# SF32LB57x register map
File version: 1.0
CPU: CM33 r0p1, little endian, MPU, FPU, 3 interrupt priority bits
Registers are 32-bit, read-write, reset 0x0 unless marked. A register's access mark holds for its fields unless they carry their own. Offsets are from the block's base; [hi:lo] are bit positions; {n}, {i} and the like mark numbered series.

## SPI1
Base 0x50095000
Same registers: SPI2 0x50096000
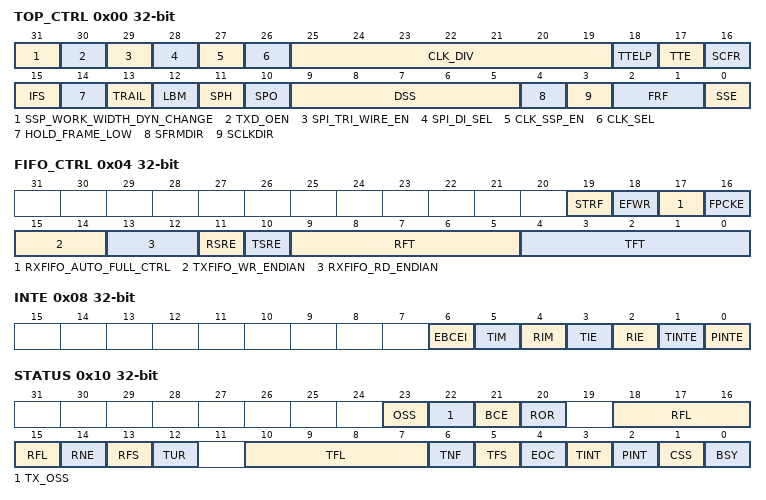
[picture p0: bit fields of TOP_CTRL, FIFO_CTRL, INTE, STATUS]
0x00 TOP_CTRL — Top Control Register
  [31] SSP_WORK_WIDTH_DYN_CHANGE — SSP_WORK_WIDTH_DYN_CHNAGE 1=SP can dynamicly change SSP_TOP_CTRL[9:5] without disabling SSP_TOP_CTRL[0] and re-enabling SSP_TOP_CTRL[0]
  [30] TXD_OEN — TXD_OEN 1=TXD is input 0=TXD is output
  [29] SPI_TRI_WIRE_EN — SPI_THREE_WIRE_MODE_EN 1=enable
  [28] SPI_DI_SEL — Select spi_di source. 0: from port DI. 1: from port DIO.
  [27] CLK_SSP_EN — write 0 to diable clk before clk setting is done
  [26] CLK_SEL — 0: select clk_div as clk_ssp 1: select clk_sys as clk_ssp
  [25:19] CLK_DIV — div ratio from clk_sys
  [18] TTELP — TXD Three-state Enable On Last Phase 0 = TXDx is three-stated 1/2 clock cycle after the beginning of the LSB 1 = TXDx output signal is three-stated on the clock edge that ends the LSB
  [17] TTE — TXD Three-State Enable 0 = TXDx output signal is not three-stated 1 = TXD is three-stated when not transmitting data
  [16] SCFR — Slave Clock Free Running 0 = Clock input to SSPSCLKx is continuously running 1 = Clock input to SSPSCLKx is only active during data transfers.
  [15] IFS — Invert Frame Signal 0 = SSPSFRMx polarity is determined by the PSP polarity bits 1 = SSPSFRMx will be inverted from normal-SSPSFRMx (as defined by the PSP polarity bits). (Works in all frame formats: SPI, SSP, and PSP)
  [14] HOLD_FRAME_LOW — Hold Frame Low Control 1=After this field is set to 1 and the SSP is operating in master mode, the output frame clock ssp_sfrm_gpio will hold low. Used for SPI and NMW Format Rx FIFO Auto Full Control, which makes the frame clock is still low during there's no bit clock, or the data transfers before the stop clock will be discarded.
  [13] TRAIL — Trailing Byte 0 = Trailing bytes are handled by the ltvar Product Number> 1 = Trailing bytes are handled by DMA bursts
  [12] LBM — Loopback Mode (Test Mode Bit) 0 = Normal serial port operation is enabled 1 = Output of TX serial shifter is internally connected to input of RX serial shifter
  [11] SPH — Motorola SPI SSPSCLK phase setting 0 = SSPSCLKx is inactive until one cycle after the start of a frame and active until 1/2 cycle before the end of a frame 1 = SSPSCLKx is inactive until 1/2 cycle after the start of a frame and active until one cycle before the end of a frame
  [10] SPO — Motorola SPI SSPSCLK Polarity Setting 0 = The inactive or idle state of SSPSCLKx is low 1 = The inactive or idle state of SSPSCLKx is high
  [9:5] DSS — SSP Work data size, register bits value 0~31 indicated data size 1~32 bits, usually use data size 8bits, 16bits, 24bits, 32bits
  [4] SFRMDIR — SSP Frame (SSPSFRMx) Direction 0 = Master mode, SSPx port drives SSPSFRMx 1 = Slave mode, SSPx port receives SSPSFRMx
  [3] SCLKDIR — SSP Serial Bit Rate Clock (SSPSCLKx) Direction 0 = Master mode, SSPx port drives SSPSCLKx 1 = Slave mode, SSPx port receives SSPSCLKx
  [2:1] FRF — Frame Format 0x0 = Motorola* Serial Peripheral Interface (SPI) 0x1 = Texas Instruments* Synchronous Serial Protocol (SSP) 0x2 = National Semiconductor Microwire* 0x3 = Frame mode
  [0] SSE — Synchronous Serial Port Enable 0 = SSPx port is disabled 1 = SSPx port is enabled
0x04 FIFO_CTRL — FIFO Control Register
  [19] STRF — Select FIFO For Efwr (Test Mode Bit) Only when the ltEnable FIFO Write/read> field = 1 0 = TXFIFO is selected for both writes and reads through the SSP Data Register 1 = RXFIFO is selected for both writes and reads through the SSP Data Register
  [18] EFWR — Enable FIFO Write/read (Test Mode Bit) 0 = FIFO write/read special function is disabled (normal SSPx operational mode) 1 = FIFO write/read special function is enabled
  [17] RXFIFO_AUTO_FULL_CTRL — Rx FIFO Auto Full Control =1After this field is set to 1 and the SSP is operating in master mode, the SSP FSM returns to IDLE state and stops the ssp_sclk_gpio. When Rx FIFO is full, the SSP FSM continues transferring data after the Rx FIFO is not full. This field is used to avoid an Rx FIFO overrun issue. 1= Enable Rx FIFO auto full control
  [16] FPCKE — FIFO Packing Enable 0 = FIFO packing mode disabled 1 = FIFO packing mode enabled
  [15:14] TXFIFO_WR_ENDIAN — apb_pwdata Write to Tx FIFO Endian 0x0 = txfifo_wdata[31:0] = apb_pwdata[31:0] 0x1 = fifo_wdata[31:0] = {apb_pwdata[15:0], apb_pwdata[31:16]} 0x2 = txfifo_wdata[31:0] = {apb_pwdata[7:0], apb_pwdata[15:8], apb_pwdata[23:16], apb_pwdata[31:24]} 0x3 = txfifo_wdata[31:0] = {apb_pwdata[23:16], apb_pwdata[31:24], apb_pwdata[7:0], apb_pwdata[15:8]}
  [13:12] RXFIFO_RD_ENDIAN — apb_prdata Read from Rx FIFO Endian 0x0 = apb_prdata[31:0] = rxfifo_wdata[31:0] 0x1 = apb_prdata[31:0] = {rxfifo_wdata[15:0], rxfifo_wdata[31:16]} 0x2 = apb_prdata[31:0]= {rxfifo_wdata[7:0], rxfifo_wdata[15:8], rxfifo_wdata[23:16], rxfifo_wdata[31:24]} 0x3 = apb_prdata[31:0]= {rxfifo_wdata[23:16], rxfifo_wdata[31:24], rxfifo_wdata[7:0], rxfifo_wdata[15:8]}
  [11] RSRE — Receive Service Request Enable 0 = DMA service request is disabled 1 = DMA service request is enabled
  [10] TSRE — Transmit Service Request Enable 0 = DMA service request is disabled 1 = DMA service request is enabled
  [9:5] RFT — RXFIFO Trigger Threshold This field sets the threshold level at which RXFIFO asserts interrupt. The level should be set to the preferred threshold value minus 1.
  [4:0] TFT — TXFIFO Trigger Threshold This field sets the threshold level at which TXFIFO asserts interrupt. The level should be set to the preferred threshold value minus 1.
0x08 INTE — Interrupt Enable Register
  [6] EBCEI — Enable Bit Count Error Interrupt 0 = Interrupt due to a bit count error is disabled 1 = Interrupt due to a bit count error is enabled
  [5] TIM — Transmit FIFO Underrun Interrupt Mask 0 = TUR events generate an SSP interrupt 1 = TUR events do NOT generate an SSP interrupt
  [4] RIM — Receive FIFO Overrun Interrupt Mask 0 = ROR events generate an SSP interrupt 1 = ROR events do NOT generate an SSP interrupt
  [3] TIE — Transmit FIFO Interrupt Enable 0 = TXFIFO threshold-level-reached interrupt is disabled 1 = TXFIFO threshold-level-reached interrupt is enabled
  [2] RIE — Receive FIFO Interrupt Enable 0 = RXFIFO threshold-level-reached interrupt is disabled 1 = RXFIFO threshold-level-reached interrupt is enabled
  [1] TINTE — Receiver Time-out Interrupt Enable 0 = Receiver time-out interrupt is disabled 1 = Receiver time-out interrupt is enabled
  [0] PINTE — Peripheral Trailing Byte Interrupt Enable 0 = Peripheral trailing byte interrupt is disabled 1 = Peripheral trailing byte interrupt is enabled
0x0C TO — SPI Time Out Register
  [23:0] TIMEOUT — Timeout Value TIMEOUT value is the value (0 to 2ltsuper 24>-1) that defines the time-out interval. The time-out interval is given by the equation shown in the TIMEOUT Interval Equation.
0x10 STATUS
  [23] OSS — Odd Sample Status 0 = RxFIFO entry has two samples 1 = RxFIFO entry has one sample Note that this bit needs to be looked at only when FIFO Packing is enabled (ltFIFO Packing Enable> field in SSP FIFO Control Register is set). Otherwise, this bit is zero. When SSPx port is in Packed mode and the CPU is used instead of DMA to read the RxFIFO, the CPU should make sure that ltReceive FIFO Not Empty> = 1 AND this field = 0 before it attempts to read the RxFIFO.
  [22] TX_OSS — TX FIFO Odd Sample Status When SSPx port is in packed mode, the number of samples in the TX FIFO is: (ltTransmit FIFO Level>*2 + this field), when ltTransmit FIFO Not Full> = 1 32, when ltTransmit FIFO Not Full> = 0. The TX FIFO cannot accept new data when ltTransmit FIFO Not Full> = 1 and ltTransmit FIFO Level> = 15 and this field = 1. (The TX FIFO has 31 samples). 0 = TxFIFO entry has an even number of samples 1 = TxFIFO entry has an odd number of samples Note that this bit needs to be read only when FIFO Packing is enabled (ltFIFO Packing Enable> in the SSP FIFO Control Register is set). Otherwise, this bit is zero.
  [21] BCE — Bit Count Error 0 = The SSPx port has not experienced a bit count error 1 = The SSPSFRMx signal was asserted when the bit counter was not zero
  [20] ROR — Receive FIFO Overrun 0 = RXFIFO has not experienced an overrun 1 = Attempted data write to full RXFIFO, causes an interrupt request
  [18:15] RFL — Receive FIFO Level This field is the number of entries minus one in RXFIFO. When the value 0x1F is read, the RXFIFO is either empty or full, and software should read the ltReceive FIFO Not Empty> field.
  [14] RNE — Receive FIFO Not Empty 0 = RXFIFO is empty 1 = RXFIFO is not empty
  [13] RFS — Receive FIFO Service Request 0 = RXFIFO level is at or below RFT threshold (RFT) or SSPx port is disabled 1 = RXFIFO level exceeds RFT threshold (RFT), causes an interrupt request
  [12] TUR — Transmit FIFO Underrun 0 = The TXFIFO has not experienced an underrun 1 = A read from the TXFIFO was attempted when the TXFIFO was empty, causes an interrupt if it is enabled (ltTransmit FIFO Underrun Interrupt Mask> in the SSP INT EN Register is 0)
  [10:7] TFL — Transmit FIFO Level This field is the number of entries in TXFIFO.When the value 0x0 is read, the TXFIFO is either empty or full, and software should read the ltTransmit FIFO Not Full> field.
  [6] TNF — Transmit FIFO Not Full 0 = TXFIFO is full 1 = TXFIFO is not full
  [5] TFS — Transmit FIFO Service Request 0 = TX FIFO level exceeds the TFT threshold (TFT + 1) or SSPx port disabled 1 = TXFIFO level is at or below TFT threshold (TFT + 1), causes an interrupt request
  [4] EOC — End Of Chain 0 = DMA has not signaled an end of chain condition 1 = DMA has signaled an end of chain condition
  [3] TINT — Receiver Time-out Interrupt 0 = No receiver time-out is pending 1 = Receiver time-out pending, causes an interrupt request
  [2] PINT — Peripheral Trailing Byte Interrupt 0 = No peripheral trailing byte interrupt is pending 1 = Peripheral trailing byte interrupt is pending
  [1] CSS — Clock Synchronization Status 0 = The SSPx port is ready for slave clock operations 1 = The SSPx port is currently busy synchronizing slave mode signals
  [0] BSY — SSP Busy 0 = SSPx port is idle or disabled 1 = SSPx port is currently transmitting or receiving framed data
0x14 DATA — SPI DATA Register
  [31:0] DATA — DATA This field is used for data to be written to the TXFIFO read from the RXFIFO.
0x18 FRM_HDR_DATA — Frame Header Register
  [31:0] HDR_DATA — frame header data, including cmd addr ect
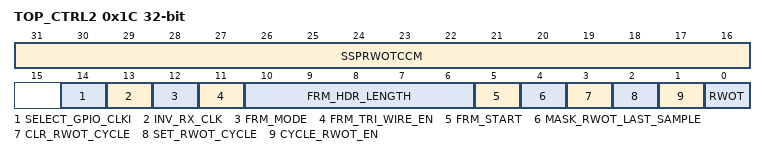
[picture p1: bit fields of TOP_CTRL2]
0x1C TOP_CTRL2 — Top CTRL Register2
  [31:16] SSPRWOTCCM — It's just total ssp_sclk_gpio Cycles The value of this register defines the total number of ssp_sclk_gpio cycles when SSP works in master and RWOT mode. When the rwot_counter matches this value, SSP returns to IDLE state and does not output ssp_sclk_gpio anymore.
  [14] SELECT_GPIO_CLKI — use clki from as rx clock
  [13] INV_RX_CLK — invert rx clk for large io timing margin
  [12] FRM_MODE — frame mode 0: rx only after header 1: tx only after header
  [11] FRM_TRI_WIRE_EN — 1: auto te switch between hdr and rx 0: 4 wire mode
  [10:6] FRM_HDR_LENGTH — frame header data length in bits:
  [5] FRM_START — frame header data, including cmd addr ect
  [4] MASK_RWOT_LAST_SAMPLE — Mask last_sample_flag in RWOT Mode 1= Mask 0 = Unmask
  [3] CLR_RWOT_CYCLE — Clear SSP Internal rwot_counter This field clears the rwot_counter to 0. This field is self cleared by SSP after SSE = 1. 1 = Clear rwot_counter
  [2] SET_RWOT_CYCLE — Set RWOT Cycle This field is used to set the value of the SSP_RWOT_CCM register to the SSP internal rwot_counter. This field is self-cleared by SSP after SSE = 1. 1 = Set rwot_counter
  [1] CYCLE_RWOT_EN — Enable SSP RWOT Cycle Counter Mode 1 = Enable
  [0] RWOT — Receive Without Transmit 0 = Transmit/receive mode 1 = Receive without transmit mode
0x20 RWOT_CVWRN — SSP RWOT Counter Value Write for Red Request Register
  [31:0] SSPRWOTCVWR — SSPRWOTCVWR This register prevents the risk of instability on rwot_counter value reading, it's only valid after SSP has been enabled Write 0 = No effect Write 1 = Capture value of rwot_counter Read: Returns the captured value of rwot_counter
